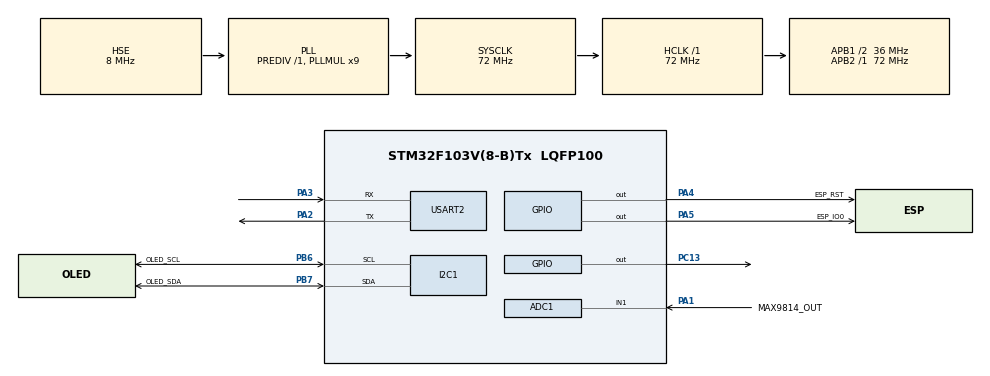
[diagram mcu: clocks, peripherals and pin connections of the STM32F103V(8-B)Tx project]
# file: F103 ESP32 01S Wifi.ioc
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ADC1.Channel-0\#ChannelRegularConversion=ADC_CHANNEL_1
ADC1.ContinuousConvMode=ENABLE
ADC1.NbrOfConversionFlag=1
ADC1.Rank-0\#ChannelRegularConversion=1
ADC1.SamplingTime-0\#ChannelRegularConversion=ADC_SAMPLETIME_239CYCLES_5
ADC1.master=1
Dma.ADC1.0.Direction=DMA_PERIPH_TO_MEMORY
Dma.ADC1.0.Instance=DMA1_Channel1
Dma.ADC1.0.MemDataAlignment=DMA_MDATAALIGN_HALFWORD
Dma.ADC1.0.MemInc=DMA_MINC_ENABLE
Dma.ADC1.0.Mode=DMA_CIRCULAR
Dma.ADC1.0.PeriphDataAlignment=DMA_PDATAALIGN_HALFWORD
Dma.ADC1.0.PeriphInc=DMA_PINC_DISABLE
Dma.ADC1.0.Priority=DMA_PRIORITY_LOW
Dma.Request0=ADC1
I2C1.I2C_Mode=I2C_Fast
IWDG.Prescaler=IWDG_PRESCALER_64
IWDG.Reload=1250
Mcu.Family=STM32F1
Mcu.Name=STM32F103V(8-B)Tx
Mcu.Package=LQFP100
NVIC.DMA1_Channel1_IRQn=true\:0\:0\:false\:false\:true\:false\:true\:true
NVIC.PriorityGroup=NVIC_PRIORITYGROUP_4
NVIC.USART2_IRQn=true\:0\:0\:false\:false\:true\:true\:true\:true
OSC_IN.Mode=HSE-External-Oscillator
OSC_IN.Signal=RCC_OSC_IN
OSC_OUT.Mode=HSE-External-Oscillator
OSC_OUT.Signal=RCC_OSC_OUT
PA1.GPIO_Label=MAX9814_OUT
PA1.Signal=SharedAnalog_PA1
PA13.Mode=Serial_Wire
PA13.Signal=SYS_JTMS-SWDIO
PA14.Mode=Serial_Wire
PA14.Signal=SYS_JTCK-SWCLK
PA2.Mode=Asynchronous
PA2.Signal=USART2_TX
PA3.Mode=Asynchronous
PA3.Signal=USART2_RX
PA4.GPIO_Label=ESP_RST
PA4.Signal=GPIO_Output
PA5.GPIO_Label=ESP_IO0
PA5.PinState=GPIO_PIN_SET
PA5.Signal=GPIO_Output
PB6.GPIO_Label=OLED_SCL
PB6.Mode=I2C
PB6.Signal=I2C1_SCL
PB7.GPIO_Label=OLED_SDA
PB7.Mode=I2C
PB7.Signal=I2C1_SDA
PC13-TAMPER-RTC.Signal=GPIO_Output
ProjectManager.HeapSize=0x200
ProjectManager.StackSize=0x400
ProjectManager.TargetToolchain=STM32CubeIDE
RCC.ADCPresc=RCC_ADCPCLK2_DIV6
RCC.AHBFreq_Value=72000000
RCC.APB1CLKDivider=RCC_HCLK_DIV2
RCC.APB1Freq_Value=36000000
RCC.APB1TimFreq_Value=72000000
RCC.APB2Freq_Value=72000000
RCC.APB2TimFreq_Value=72000000
RCC.HCLKFreq_Value=72000000
RCC.PLLMUL=RCC_PLL_MUL9
RCC.PLLSourceVirtual=RCC_PLLSOURCE_HSE
RCC.SYSCLKFreq_VALUE=72000000
RCC.SYSCLKSource=RCC_SYSCLKSOURCE_PLLCLK
RCC.USBFreq_Value=72000000
SH.SharedAnalog_PA1.0=GPIO_Analog
SH.SharedAnalog_PA1.1=ADC1_IN1,IN1
USART2.VirtualMode=VM_ASYNC
VP_IWDG_VS_IWDG.Mode=IWDG_Activate
board=custom

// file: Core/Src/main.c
/* USER CODE BEGIN Header */
/**
  ******************************************************************************
  * @file           : main.c
  * @brief          : Main program body
  ******************************************************************************
  * @attention
  *
  * Copyright (c) 2026 STMicroelectronics.
  * All rights reserved.
  *
  * This software is licensed under terms that can be found in the LICENSE file
  * in the root directory of this software component.
  * If no LICENSE file comes with this software, it is provided AS-IS.
  *
  ******************************************************************************
  */
/* USER CODE END Header */
#include "main.h"

/* USER CODE BEGIN Includes */
#include "general.h"
//#include "oled.h"
/* USER CODE END Includes */

ADC_HandleTypeDef hadc1;
DMA_HandleTypeDef hdma_adc1;

I2C_HandleTypeDef hi2c1;

IWDG_HandleTypeDef hiwdg;

UART_HandleTypeDef huart2;

/* USER CODE BEGIN PV */
IWDG_HandleTypeDef hiwdg;
/* USER CODE END PV */

void SystemClock_Config(void);
static void MX_GPIO_Init(void);
static void MX_DMA_Init(void);
static void MX_USART2_UART_Init(void);
static void MX_I2C1_Init(void);
static void MX_ADC1_Init(void);
static void MX_IWDG_Init(void);

int main(void)
{

  /* MCU Configuration--------------------------------------------------------*/

  /* Reset of all peripherals, Initializes the Flash interface and the Systick. */
  HAL_Init();

  /* Configure the system clock */
  SystemClock_Config();

  /* Initialize all configured peripherals */
  MX_GPIO_Init();
  MX_DMA_Init();
  MX_USART2_UART_Init();
  MX_I2C1_Init();
  MX_ADC1_Init();
  MX_IWDG_Init();
  /* USER CODE BEGIN 2 */
  MX_IWDG_Init();
  General_Init(&hi2c1);

  /* USER CODE END 2 */

  /* Infinite loop */
  /* USER CODE BEGIN WHILE */
  while (1)
  {
	  General_Run();
	  HAL_IWDG_Refresh(&hiwdg);
    /* USER CODE END WHILE */

  }
}

void SystemClock_Config(void)
{
  RCC_OscInitTypeDef RCC_OscInitStruct = {0};
  RCC_ClkInitTypeDef RCC_ClkInitStruct = {0};
  RCC_PeriphCLKInitTypeDef PeriphClkInit = {0};

  /** Initializes the RCC Oscillators according to the specified parameters
  * in the RCC_OscInitTypeDef structure.
  */
  RCC_OscInitStruct.OscillatorType = RCC_OSCILLATORTYPE_LSI|RCC_OSCILLATORTYPE_HSE;
  RCC_OscInitStruct.HSEState = RCC_HSE_ON;
  RCC_OscInitStruct.HSEPredivValue = RCC_HSE_PREDIV_DIV1;
  RCC_OscInitStruct.HSIState = RCC_HSI_ON;
  RCC_OscInitStruct.LSIState = RCC_LSI_ON;
  RCC_OscInitStruct.PLL.PLLState = RCC_PLL_ON;
  RCC_OscInitStruct.PLL.PLLSource = RCC_PLLSOURCE_HSE;
  RCC_OscInitStruct.PLL.PLLMUL = RCC_PLL_MUL9;
  if (HAL_RCC_OscConfig(&RCC_OscInitStruct) != HAL_OK)
  {
    Error_Handler();
  }

  /** Initializes the CPU, AHB and APB buses clocks
  */
  RCC_ClkInitStruct.ClockType = RCC_CLOCKTYPE_HCLK|RCC_CLOCKTYPE_SYSCLK
                              |RCC_CLOCKTYPE_PCLK1|RCC_CLOCKTYPE_PCLK2;
  RCC_ClkInitStruct.SYSCLKSource = RCC_SYSCLKSOURCE_PLLCLK;
  RCC_ClkInitStruct.AHBCLKDivider = RCC_SYSCLK_DIV1;
  RCC_ClkInitStruct.APB1CLKDivider = RCC_HCLK_DIV2;
  RCC_ClkInitStruct.APB2CLKDivider = RCC_HCLK_DIV1;

  if (HAL_RCC_ClockConfig(&RCC_ClkInitStruct, FLASH_LATENCY_2) != HAL_OK)
  {
    Error_Handler();
  }
  PeriphClkInit.PeriphClockSelection = RCC_PERIPHCLK_ADC;
  PeriphClkInit.AdcClockSelection = RCC_ADCPCLK2_DIV6;
  if (HAL_RCCEx_PeriphCLKConfig(&PeriphClkInit) != HAL_OK)
  {
    Error_Handler();
  }
}

static void MX_ADC1_Init(void)
{

  ADC_ChannelConfTypeDef sConfig = {0};

  /** Common config
  */
  hadc1.Instance = ADC1;
  hadc1.Init.ScanConvMode = ADC_SCAN_DISABLE;
  hadc1.Init.ContinuousConvMode = ENABLE;
  hadc1.Init.DiscontinuousConvMode = DISABLE;
  hadc1.Init.ExternalTrigConv = ADC_SOFTWARE_START;
  hadc1.Init.DataAlign = ADC_DATAALIGN_RIGHT;
  hadc1.Init.NbrOfConversion = 1;
  if (HAL_ADC_Init(&hadc1) != HAL_OK)
  {
    Error_Handler();
  }

  /** Configure Regular Channel
  */
  sConfig.Channel = ADC_CHANNEL_1;
  sConfig.Rank = ADC_REGULAR_RANK_1;
  sConfig.SamplingTime = ADC_SAMPLETIME_239CYCLES_5;
  if (HAL_ADC_ConfigChannel(&hadc1, &sConfig) != HAL_OK)
  {
    Error_Handler();
  }

}

static void MX_I2C1_Init(void)
{

  hi2c1.Instance = I2C1;
  hi2c1.Init.ClockSpeed = 400000;
  hi2c1.Init.DutyCycle = I2C_DUTYCYCLE_2;
  hi2c1.Init.OwnAddress1 = 0;
  hi2c1.Init.AddressingMode = I2C_ADDRESSINGMODE_7BIT;
  hi2c1.Init.DualAddressMode = I2C_DUALADDRESS_DISABLE;
  hi2c1.Init.OwnAddress2 = 0;
  hi2c1.Init.GeneralCallMode = I2C_GENERALCALL_DISABLE;
  hi2c1.Init.NoStretchMode = I2C_NOSTRETCH_DISABLE;
  if (HAL_I2C_Init(&hi2c1) != HAL_OK)
  {
    Error_Handler();
  }

}

static void MX_IWDG_Init(void)
{

  hiwdg.Instance = IWDG;
  hiwdg.Init.Prescaler = IWDG_PRESCALER_64;
  hiwdg.Init.Reload = 2560;
  if (HAL_IWDG_Init(&hiwdg) != HAL_OK)
  {
    Error_Handler();
  }

}

static void MX_USART2_UART_Init(void)
{

  huart2.Instance = USART2;
  huart2.Init.BaudRate = 115200;
  huart2.Init.WordLength = UART_WORDLENGTH_8B;
  huart2.Init.StopBits = UART_STOPBITS_1;
  huart2.Init.Parity = UART_PARITY_NONE;
  huart2.Init.Mode = UART_MODE_TX_RX;
  huart2.Init.HwFlowCtl = UART_HWCONTROL_NONE;
  huart2.Init.OverSampling = UART_OVERSAMPLING_16;
  if (HAL_UART_Init(&huart2) != HAL_OK)
  {
    Error_Handler();
  }

}

static void MX_DMA_Init(void)
{

  /* DMA controller clock enable */
  __HAL_RCC_DMA1_CLK_ENABLE();

  /* DMA interrupt init */
  /* DMA1_Channel1_IRQn interrupt configuration */
  HAL_NVIC_SetPriority(DMA1_Channel1_IRQn, 0, 0);
  HAL_NVIC_EnableIRQ(DMA1_Channel1_IRQn);

}

static void MX_GPIO_Init(void)
{
  GPIO_InitTypeDef GPIO_InitStruct = {0};

  /* GPIO Ports Clock Enable */
  __HAL_RCC_GPIOC_CLK_ENABLE();
  __HAL_RCC_GPIOA_CLK_ENABLE();
  __HAL_RCC_GPIOB_CLK_ENABLE();

  /*Configure GPIO pin Output Level */
  HAL_GPIO_WritePin(GPIOC, GPIO_PIN_13, GPIO_PIN_RESET);

  /*Configure GPIO pin Output Level */
  HAL_GPIO_WritePin(ESP_RST_GPIO_Port, ESP_RST_Pin, GPIO_PIN_RESET);

  /*Configure GPIO pin Output Level */
  HAL_GPIO_WritePin(ESP_IO0_GPIO_Port, ESP_IO0_Pin, GPIO_PIN_SET);

  /*Configure GPIO pin : PC13 */
  GPIO_InitStruct.Pin = GPIO_PIN_13;
  GPIO_InitStruct.Mode = GPIO_MODE_OUTPUT_PP;
  GPIO_InitStruct.Pull = GPIO_NOPULL;
  GPIO_InitStruct.Speed = GPIO_SPEED_FREQ_LOW;
  HAL_GPIO_Init(GPIOC, &GPIO_InitStruct);

  /*Configure GPIO pins : ESP_RST_Pin ESP_IO0_Pin */
  GPIO_InitStruct.Pin = ESP_RST_Pin|ESP_IO0_Pin;
  GPIO_InitStruct.Mode = GPIO_MODE_OUTPUT_PP;
  GPIO_InitStruct.Pull = GPIO_NOPULL;
  GPIO_InitStruct.Speed = GPIO_SPEED_FREQ_LOW;
  HAL_GPIO_Init(GPIOA, &GPIO_InitStruct);

}

void Error_Handler(void)
{
  __disable_irq();
  while (1)
  {
  }
}
